# f28p65x_flash_ctrl_regs register map
Vendor: Texas Instruments
Peripheral module from a debugger description file (folder C2000).
Address unit: 16 bits
Registers are 32-bit, read-write, no defined reset value unless marked. A register's access mark holds for its fields unless they carry their own. Offsets are as the file gives them; lines under a group give offsets from that group; [hi:lo] are bit positions; {n}, {i} and the like mark numbered series; 'fields as' and 'values as' point back to an identical list; <NAME> marks a mode.

## FLASH_CTRL_REGS — FLASH CTRL Registers
0x00 FRDCNTL — Flash Read Control Register
  [11:8] RWAIT — Random Read Waitstate
0x04 FLPROT — Flash program/erase protect register
  [0] FLWEPROT — Flash write/erase protect bit.
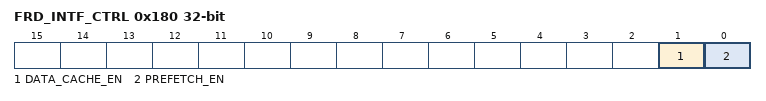
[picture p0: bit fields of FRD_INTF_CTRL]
0x180 FRD_INTF_CTRL — Flash Read Interface Control Register
  [1] DATA_CACHE_EN — Data Cache Enable
  [0] PREFETCH_EN — Prefetch Enable
